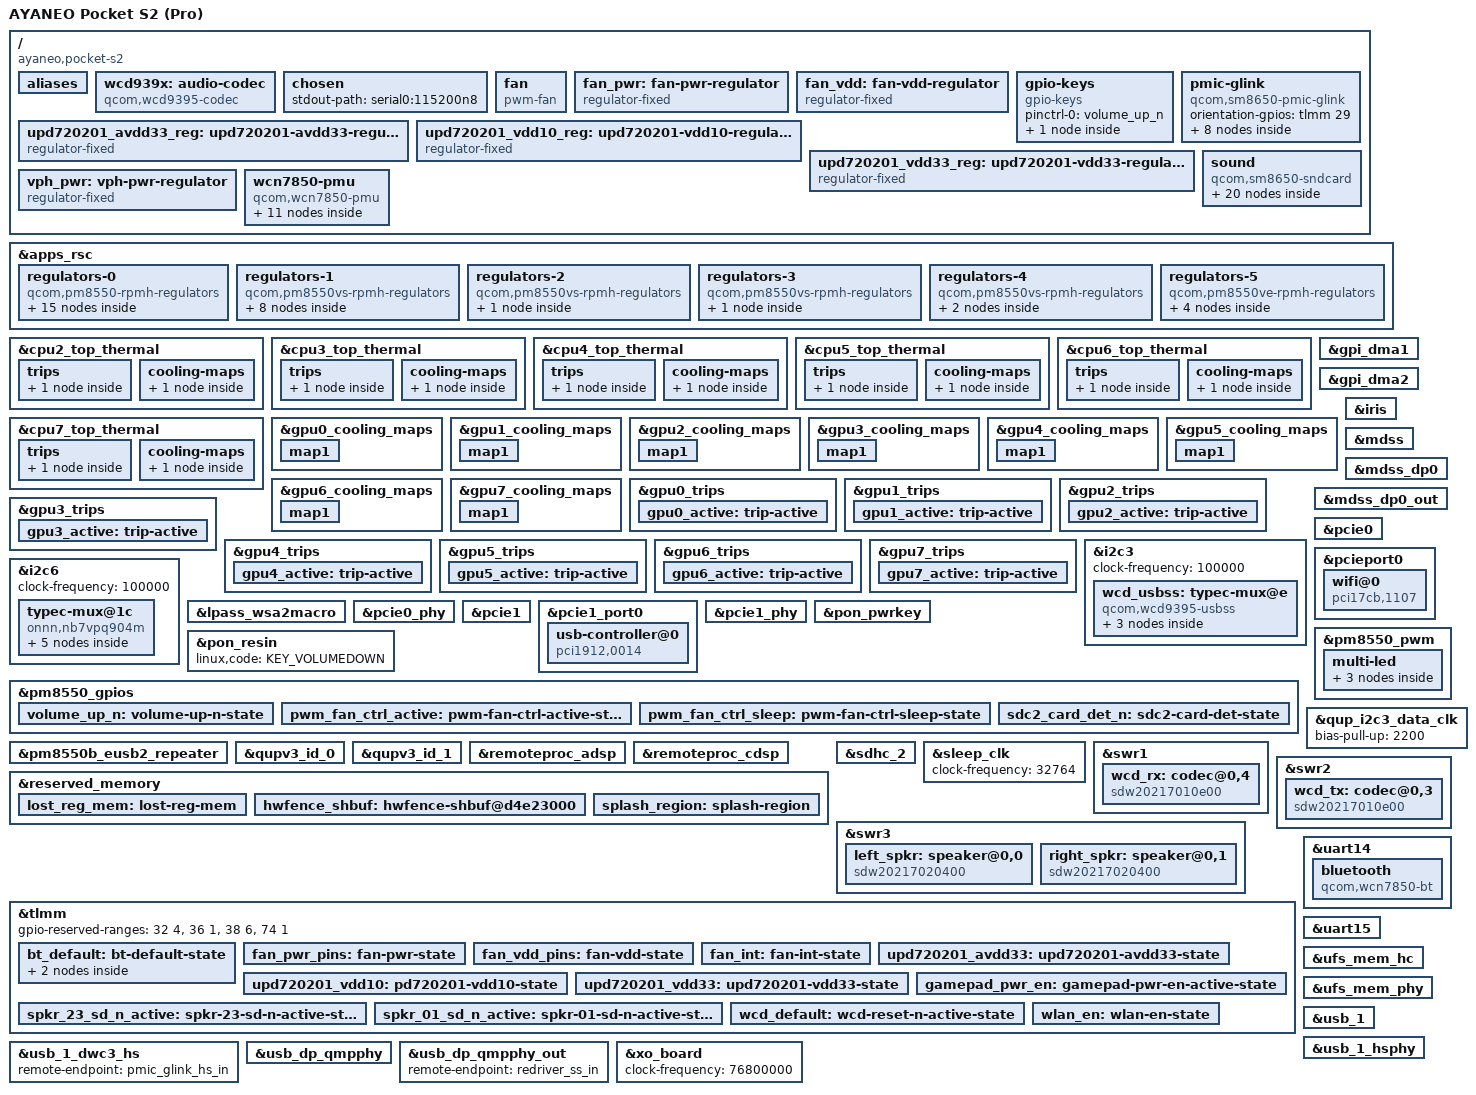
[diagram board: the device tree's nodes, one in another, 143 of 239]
// SPDX-License-Identifier: BSD-3-Clause
/*
 * Copyright (c) 2023, Linaro Limited
 * Copyright (c) 2025, Kancy Joe <kancy2333@outlook.com>
 */

/dts-v1/;

#include <dt-bindings/leds/common.h>
#include <dt-bindings/pinctrl/qcom,pmic-gpio.h>
#include <dt-bindings/regulator/qcom,rpmh-regulator.h>
#include "sm8650.dtsi"
#include "pm8550.dtsi"
#include "pm8550b.dtsi"
#define PMK8550VE_SID 8
#include "pm8550ve.dtsi"
#include "pm8550vs.dtsi"
#include "pmk8550.dtsi"

/delete-node/ &rmtfs_mem;
/delete-node/ &hwfence_shbuf;

/ {
	model = "AYANEO Pocket S2 (Pro)";
	compatible = "ayaneo,pocket-s2", "qcom,sm8650";
	chassis-type = "handset";

	aliases {
		serial0 = &uart15;
		serial1 = &uart14;
	};

	wcd939x: audio-codec {
		compatible = "qcom,wcd9395-codec", "qcom,wcd9390-codec";

		pinctrl-0 = <&wcd_default>;
		pinctrl-names = "default";

		qcom,micbias1-microvolt = <1800000>;
		qcom,micbias2-microvolt = <1800000>;
		qcom,micbias3-microvolt = <1800000>;
		qcom,micbias4-microvolt = <1800000>;
		qcom,mbhc-buttons-vthreshold-microvolt = <75000 150000 237000 500000 500000 500000 500000 500000>;
		qcom,mbhc-headset-vthreshold-microvolt = <1700000>;
		qcom,mbhc-headphone-vthreshold-microvolt = <50000>;
		qcom,rx-device = <&wcd_rx>;
		qcom,tx-device = <&wcd_tx>;

		reset-gpios = <&tlmm 107 GPIO_ACTIVE_LOW>;

		vdd-buck-supply = <&vreg_l15b_1p8>;
		vdd-rxtx-supply = <&vreg_l15b_1p8>;
		vdd-io-supply = <&vreg_l15b_1p8>;
		vdd-mic-bias-supply = <&vreg_bob1>;

		#sound-dai-cells = <1>;
	};

	chosen {
		stdout-path = "serial0:115200n8";
	};

	fan: fan {
		compatible = "pwm-fan";

		interrupts-extended = <&tlmm 14 IRQ_TYPE_EDGE_FALLING>;

		pwms = <&pm8550_pwm 3 50000>;

		fan-supply = <&fan_pwr>;

		#cooling-cells = <2>;
		cooling-levels = <0 16 32 45 60 80 105 130 155 180 205 230 255>;

		pinctrl-0 = <&fan_int>, <&pwm_fan_ctrl_active>;
		pinctrl-1 = <&pwm_fan_ctrl_sleep>;
		pinctrl-names = "default", "sleep";
	};

	fan_pwr: fan-pwr-regulator {
		compatible = "regulator-fixed";

		regulator-name = "fan_pwr";
		regulator-min-microvolt = <5000000>;
		regulator-max-microvolt = <5000000>;

		gpios = <&tlmm 125 GPIO_ACTIVE_HIGH>;
		enable-active-high;

		vin-supply = <&fan_vdd>;

		pinctrl-0 = <&fan_pwr_pins>;
		pinctrl-names = "default";
	};

	fan_vdd: fan-vdd-regulator {
		compatible = "regulator-fixed";

		regulator-name = "fan_vdd";
		regulator-min-microvolt = <5000000>;
		regulator-max-microvolt = <5000000>;

		gpios = <&tlmm 124 GPIO_ACTIVE_HIGH>;
		enable-active-high;

		vin-supply = <&vph_pwr>;

		pinctrl-0 = <&fan_vdd_pins>;
		pinctrl-names = "default";
	};

	gpio-keys {
		compatible = "gpio-keys";

		pinctrl-0 = <&volume_up_n>;
		pinctrl-names = "default";

		key-volume-up {
			label = "Volume Up";
			linux,code = <KEY_VOLUMEUP>;
			gpios = <&pm8550_gpios 6 GPIO_ACTIVE_LOW>;
			debounce-interval = <15>;
			linux,can-disable;
			wakeup-source;
		};
	};

	pmic-glink {
		compatible = "qcom,sm8650-pmic-glink",
			     "qcom,sm8550-pmic-glink",
			     "qcom,pmic-glink";
		#address-cells = <1>;
		#size-cells = <0>;

		orientation-gpios = <&tlmm 29 GPIO_ACTIVE_HIGH>;

		connector@0 {
			compatible = "usb-c-connector";
			reg = <0>;

			power-role = "dual";
			data-role = "dual";

			ports {
				#address-cells = <1>;
				#size-cells = <0>;

				port@0 {
					reg = <0>;

					pmic_glink_hs_in: endpoint {
						remote-endpoint = <&usb_1_dwc3_hs>;
					};
				};

				port@1 {
					reg = <1>;

					pmic_glink_ss_in: endpoint {
						remote-endpoint = <&redriver_ss_out>;
					};
				};

				port@2 {
					reg = <2>;

					pmic_glink_sbu: endpoint {
						remote-endpoint = <&wcd_usbss_sbu_mux>;
					};
				};
			};
		};
	};

	upd720201_avdd33_reg: upd720201-avdd33-regulator {
		compatible = "regulator-fixed";

		regulator-name = "upd720201_avdd33";
		regulator-min-microvolt = <3300000>;
		regulator-max-microvolt = <3300000>;

		gpios = <&tlmm 123 GPIO_ACTIVE_HIGH>;
		enable-active-high;

		vin-supply = <&vph_pwr>;

		pinctrl-0 = <&upd720201_avdd33>;
		pinctrl-names = "default";
	};

	upd720201_vdd10_reg: upd720201-vdd10-regulator {
		compatible = "regulator-fixed";

		regulator-name = "upd720201_vdd10";
		regulator-min-microvolt = <1050000>;
		regulator-max-microvolt = <1050000>;

		gpios = <&tlmm 122 GPIO_ACTIVE_HIGH>;
		enable-active-high;

		vin-supply = <&vph_pwr>;

		pinctrl-0 = <&upd720201_vdd10>;
		pinctrl-names = "default";
	};

	upd720201_vdd33_reg: upd720201-vdd33-regulator {
		compatible = "regulator-fixed";

		regulator-name = "upd720201_vdd33";
		regulator-min-microvolt = <3300000>;
		regulator-max-microvolt = <3300000>;

		gpios = <&tlmm 121 GPIO_ACTIVE_HIGH>;
		enable-active-high;

		vin-supply = <&vph_pwr>;

		pinctrl-0 = <&upd720201_vdd33>;
		pinctrl-names = "default";
	};

	sound {
		compatible = "qcom,sm8650-sndcard", "qcom,sm8450-sndcard";
		model = "SM8650-APS2";
		audio-routing = "SpkrLeft IN", "WSA_SPK1 OUT",
				"SpkrRight IN", "WSA_SPK2 OUT",
				"IN1_HPHL", "HPHL_OUT",
				"IN2_HPHR", "HPHR_OUT",
				"AMIC1", "MIC BIAS1",
				"AMIC2", "MIC BIAS2",
				"AMIC3", "MIC BIAS3",
				"AMIC4", "MIC BIAS3",
				"AMIC5", "MIC BIAS4",
				"TX SWR_INPUT0", "ADC1_OUTPUT",
				"TX SWR_INPUT1", "ADC2_OUTPUT",
				"TX SWR_INPUT7", "DMIC1_OUTPUT",
				"TX SWR_INPUT8", "DMIC2_OUTPUT";

		wcd-playback-dai-link {
			link-name = "WCD Playback";

			codec {
				sound-dai = <&wcd939x 0>,
					    <&swr1 0>,
					    <&lpass_rxmacro 0>;
			};

			cpu {
				sound-dai = <&q6apmbedai RX_CODEC_DMA_RX_0>;
			};

			platform {
				sound-dai = <&q6apm>;
			};
		};

		wcd-capture-dai-link {
			link-name = "WCD Capture";
			codec {
				sound-dai = <&wcd939x 1>,
					    <&swr2 0>,
					    <&lpass_txmacro 0>;
			};

			cpu {
				sound-dai = <&q6apmbedai TX_CODEC_DMA_TX_3>;
			};


			platform {
				sound-dai = <&q6apm>;
			};
		};

		wsa-dai-link {
			link-name = "WSA Playback";

			codec {
				sound-dai = <&right_spkr>,
					    <&left_spkr>,
					    <&swr3 0>,
					    <&lpass_wsa2macro 0>;
			};

			cpu {
				sound-dai = <&q6apmbedai WSA_CODEC_DMA_RX_0>;
			};

			platform {
				sound-dai = <&q6apm>;
			};
		};

		va-dai-link {
			link-name = "VA Capture";

			codec {
				sound-dai = <&lpass_vamacro 0>;
			};

			cpu {
				sound-dai = <&q6apmbedai VA_CODEC_DMA_TX_0>;
			};

			platform {
				sound-dai = <&q6apm>;
			};
		};

		dp-dai-link {
			link-name = "DisplayPort Playback";

			codec {
				sound-dai = <&mdss_dp0>;
			};

			cpu {
				sound-dai = <&q6apmbedai DISPLAY_PORT_RX_0>;
			};

			platform {
				sound-dai = <&q6apm>;
			};
		};
	};

	vph_pwr: vph-pwr-regulator {
		compatible = "regulator-fixed";

		regulator-name = "vph_pwr";
		regulator-min-microvolt = <3700000>;
		regulator-max-microvolt = <3700000>;

		regulator-always-on;
		regulator-boot-on;
	};

	wcn7850-pmu {
		compatible = "qcom,wcn7850-pmu";

		pinctrl-names = "default";
		pinctrl-0 = <&wlan_en>, <&bt_default>;

		wlan-enable-gpios = <&tlmm 16 GPIO_ACTIVE_HIGH>;
		bt-enable-gpios = <&tlmm 17 GPIO_ACTIVE_HIGH>;

		vdd-supply = <&vreg_s4i_0p85>;
		vddio-supply = <&vreg_l15b_1p8>;
		vddio1p2-supply = <&vreg_l3c_1p2>;
		vddaon-supply = <&vreg_s2c_0p8>;
		vdddig-supply = <&vreg_s3c_0p9>;
		vddrfa1p2-supply = <&vreg_s1c_1p2>;
		vddrfa1p8-supply = <&vreg_s6c_1p8>;

		clocks = <&rpmhcc RPMH_RF_CLK1>;

		regulators {
			vreg_pmu_rfa_cmn: ldo0 {
				regulator-name = "vreg_pmu_rfa_cmn";
			};

			vreg_pmu_aon_0p59: ldo1 {
				regulator-name = "vreg_pmu_aon_0p59";
			};

			vreg_pmu_wlcx_0p8: ldo2 {
				regulator-name = "vreg_pmu_wlcx_0p8";
			};

			vreg_pmu_wlmx_0p85: ldo3 {
				regulator-name = "vreg_pmu_wlmx_0p85";
			};

			vreg_pmu_btcmx_0p85: ldo4 {
				regulator-name = "vreg_pmu_btcmx_0p85";
			};

			vreg_pmu_rfa_0p8: ldo5 {
				regulator-name = "vreg_pmu_rfa_0p8";
			};

			vreg_pmu_rfa_1p2: ldo6 {
				regulator-name = "vreg_pmu_rfa_1p2";
			};

			vreg_pmu_rfa_1p8: ldo7 {
				regulator-name = "vreg_pmu_rfa_1p8";
			};

			vreg_pmu_pcie_0p9: ldo8 {
				regulator-name = "vreg_pmu_pcie_0p9";
			};

			vreg_pmu_pcie_1p8: ldo9 {
				regulator-name = "vreg_pmu_pcie_1p8";
			};
		};
	};
};

&apps_rsc {
	regulators-0 {
		compatible = "qcom,pm8550-rpmh-regulators";

		vdd-bob1-supply = <&vph_pwr>;
		vdd-bob2-supply = <&vph_pwr>;
		vdd-l2-l13-l14-supply = <&vreg_bob1>;
		vdd-l3-supply = <&vreg_s1c_1p2>;
		vdd-l5-l16-supply = <&vreg_bob1>;
		vdd-l6-l7-supply = <&vreg_bob1>;
		vdd-l8-l9-supply = <&vreg_bob1>;
		vdd-l11-supply = <&vreg_s1c_1p2>;
		vdd-l12-supply = <&vreg_s6c_1p8>;
		vdd-l15-supply = <&vreg_s6c_1p8>;
		vdd-l17-supply = <&vreg_bob2>;

		qcom,pmic-id = "b";

		vreg_bob1: bob1 {
			regulator-name = "vreg_bob1";
			regulator-min-microvolt = <3296000>;
			regulator-max-microvolt = <3960000>;
			regulator-initial-mode = <RPMH_REGULATOR_MODE_HPM>;
		};

		vreg_bob2: bob2 {
			regulator-name = "vreg_bob2";
			regulator-min-microvolt = <2720000>;
			regulator-max-microvolt = <3008000>;
			regulator-initial-mode = <RPMH_REGULATOR_MODE_HPM>;
		};

		vreg_l2b_3p0: ldo2 {
			regulator-name = "vreg_l2b_3p0";
			regulator-min-microvolt = <3008000>;
			regulator-max-microvolt = <3008000>;
			regulator-initial-mode = <RPMH_REGULATOR_MODE_HPM>;
			regulator-allow-set-load;
			regulator-allowed-modes = <RPMH_REGULATOR_MODE_LPM
						   RPMH_REGULATOR_MODE_HPM>;
		};

		vreg_l5b_3p1: ldo5 {
			regulator-name = "vreg_l5b_3p1";
			regulator-min-microvolt = <3104000>;
			regulator-max-microvolt = <3104000>;
			regulator-initial-mode = <RPMH_REGULATOR_MODE_HPM>;
			regulator-allow-set-load;
			regulator-allowed-modes = <RPMH_REGULATOR_MODE_LPM
						   RPMH_REGULATOR_MODE_HPM>;
		};

		vreg_l6b_1p8: ldo6 {
			regulator-name = "vreg_l6b_1p8";
			regulator-min-microvolt = <1800000>;
			regulator-max-microvolt = <3008000>;
			regulator-initial-mode = <RPMH_REGULATOR_MODE_HPM>;
			regulator-allow-set-load;
			regulator-allowed-modes = <RPMH_REGULATOR_MODE_LPM
						   RPMH_REGULATOR_MODE_HPM>;
		};

		vreg_l7b_1p8: ldo7 {
			regulator-name = "vreg_l7b_1p8";
			regulator-min-microvolt = <1800000>;
			regulator-max-microvolt = <3008000>;
			regulator-initial-mode = <RPMH_REGULATOR_MODE_HPM>;
		};

		vreg_l8b_1p8: ldo8 {
			regulator-name = "vreg_l8b_1p8";
			regulator-min-microvolt = <1800000>;
			regulator-max-microvolt = <3008000>;
			regulator-initial-mode = <RPMH_REGULATOR_MODE_HPM>;
			regulator-allow-set-load;
			regulator-allowed-modes = <RPMH_REGULATOR_MODE_LPM
						   RPMH_REGULATOR_MODE_HPM>;
		};

		vreg_l9b_2p9: ldo9 {
			regulator-name = "vreg_l9b_2p9";
			regulator-min-microvolt = <2960000>;
			regulator-max-microvolt = <3008000>;
			regulator-initial-mode = <RPMH_REGULATOR_MODE_HPM>;
			regulator-allow-set-load;
			regulator-allowed-modes = <RPMH_REGULATOR_MODE_LPM
						   RPMH_REGULATOR_MODE_HPM>;
		};

		vreg_l11b_1p2: ldo11 {
			regulator-name = "vreg_l11b_1p2";
			regulator-min-microvolt = <1200000>;
			regulator-max-microvolt = <1504000>;
			regulator-initial-mode = <RPMH_REGULATOR_MODE_HPM>;
			regulator-allow-set-load;
			regulator-allowed-modes = <RPMH_REGULATOR_MODE_LPM
						   RPMH_REGULATOR_MODE_HPM>;
		};

		vreg_l12b_1p8: ldo12 {
			regulator-name = "vreg_l12b_1p8";
			regulator-min-microvolt = <1800000>;
			regulator-max-microvolt = <1800000>;
			regulator-initial-mode = <RPMH_REGULATOR_MODE_HPM>;
			regulator-allow-set-load;
			regulator-allowed-modes = <RPMH_REGULATOR_MODE_LPM
						   RPMH_REGULATOR_MODE_HPM>;
		};

		vreg_l13b_3p0: ldo13 {
			regulator-name = "vreg_l13b_3p0";
			regulator-min-microvolt = <3000000>;
			regulator-max-microvolt = <3000000>;
			regulator-initial-mode = <RPMH_REGULATOR_MODE_HPM>;
			regulator-allow-set-load;
			regulator-allowed-modes = <RPMH_REGULATOR_MODE_LPM
						   RPMH_REGULATOR_MODE_HPM>;
		};

		vreg_l14b_3p2: ldo14 {
			regulator-name = "vreg_l14b_3p2";
			regulator-min-microvolt = <3200000>;
			regulator-max-microvolt = <3200000>;
			regulator-initial-mode = <RPMH_REGULATOR_MODE_HPM>;
			regulator-allow-set-load;
			regulator-allowed-modes = <RPMH_REGULATOR_MODE_LPM
						   RPMH_REGULATOR_MODE_HPM>;
		};

		vreg_l15b_1p8: ldo15 {
			regulator-name = "vreg_l15b_1p8";
			regulator-min-microvolt = <1800000>;
			regulator-max-microvolt = <1800000>;
			regulator-initial-mode = <RPMH_REGULATOR_MODE_HPM>;
			regulator-allow-set-load;
			regulator-allowed-modes = <RPMH_REGULATOR_MODE_LPM
						   RPMH_REGULATOR_MODE_HPM>;
		};

		vreg_l16b_2p8: ldo16 {
			regulator-name = "vreg_l16b_2p8";
			regulator-min-microvolt = <2800000>;
			regulator-max-microvolt = <2800000>;
			regulator-initial-mode = <RPMH_REGULATOR_MODE_HPM>;
			regulator-allow-set-load;
			regulator-allowed-modes = <RPMH_REGULATOR_MODE_LPM
						   RPMH_REGULATOR_MODE_HPM>;
			regulator-always-on;
			regulator-boot-on;
		};

		vreg_l17b_2p5: ldo17 {
			regulator-name = "vreg_l17b_2p5";
			regulator-min-microvolt = <2504000>;
			regulator-max-microvolt = <2504000>;
			regulator-initial-mode = <RPMH_REGULATOR_MODE_HPM>;
			regulator-allow-set-load;
			regulator-allowed-modes = <RPMH_REGULATOR_MODE_LPM
						   RPMH_REGULATOR_MODE_HPM>;
		};
	};

	regulators-1 {
		compatible = "qcom,pm8550vs-rpmh-regulators";

		vdd-l1-supply = <&vreg_s1c_1p2>;
		vdd-l2-supply = <&vreg_s1c_1p2>;
		vdd-l3-supply = <&vreg_s1c_1p2>;
		vdd-s1-supply = <&vph_pwr>;
		vdd-s2-supply = <&vph_pwr>;
		vdd-s3-supply = <&vph_pwr>;
		vdd-s4-supply = <&vph_pwr>;
		vdd-s5-supply = <&vph_pwr>;
		vdd-s6-supply = <&vph_pwr>;

		qcom,pmic-id = "c";

		vreg_s1c_1p2: smps1 {
			regulator-name = "vreg_s1c_1p2";
			regulator-min-microvolt = <1256000>;
			regulator-max-microvolt = <1348000>;
			regulator-initial-mode = <RPMH_REGULATOR_MODE_HPM>;
		};

		vreg_s2c_0p8: smps2 {
			regulator-name = "vreg_s2c_0p8";
			regulator-min-microvolt = <852000>;
			regulator-max-microvolt = <1036000>;
			regulator-initial-mode = <RPMH_REGULATOR_MODE_HPM>;
		};

		vreg_s3c_0p9: smps3 {
			regulator-name = "vreg_s3c_0p9";
			regulator-min-microvolt = <976000>;
			regulator-max-microvolt = <1064000>;
			regulator-initial-mode = <RPMH_REGULATOR_MODE_HPM>;
		};

		vreg_s4c_1p2: smps4 {
			regulator-name = "vreg_s4c_1p2";
			regulator-min-microvolt = <1224000>;
			regulator-max-microvolt = <1280000>;
			regulator-initial-mode = <RPMH_REGULATOR_MODE_HPM>;
		};

		vreg_s5c_0p7: smps5 {
			regulator-name = "vreg_s5c_0p7";
			regulator-min-microvolt = <752000>;
			regulator-max-microvolt = <900000>;
			regulator-initial-mode = <RPMH_REGULATOR_MODE_HPM>;
		};

		vreg_s6c_1p8: smps6 {
			regulator-name = "vreg_s6c_1p8";
			regulator-min-microvolt = <1856000>;
			regulator-max-microvolt = <2000000>;
			regulator-initial-mode = <RPMH_REGULATOR_MODE_HPM>;
		};

		vreg_l1c_1p2: ldo1 {
			regulator-name = "vreg_l1c_1p2";
			regulator-min-microvolt = <1200000>;
			regulator-max-microvolt = <1200000>;
			regulator-initial-mode = <RPMH_REGULATOR_MODE_HPM>;
			regulator-allow-set-load;
			regulator-allowed-modes = <RPMH_REGULATOR_MODE_LPM
						   RPMH_REGULATOR_MODE_HPM>;
		};

		vreg_l3c_1p2: ldo3 {
			regulator-name = "vreg_l3c_1p2";
			regulator-min-microvolt = <1200000>;
			regulator-max-microvolt = <1200000>;
			regulator-initial-mode = <RPMH_REGULATOR_MODE_HPM>;
			regulator-allow-set-load;
			regulator-allowed-modes = <RPMH_REGULATOR_MODE_LPM
						   RPMH_REGULATOR_MODE_HPM>;
			regulator-always-on;
			regulator-boot-on;
		};
	};

	regulators-2 {
		compatible = "qcom,pm8550vs-rpmh-regulators";

		vdd-l1-supply = <&vreg_s3c_0p9>;

		qcom,pmic-id = "d";

		vreg_l1d_0p88: ldo1 {
			regulator-name = "vreg_l1d_0p88";
			regulator-min-microvolt = <912000>;
			regulator-max-microvolt = <920000>;
			regulator-initial-mode = <RPMH_REGULATOR_MODE_HPM>;
			regulator-allow-set-load;
			regulator-allowed-modes = <RPMH_REGULATOR_MODE_LPM
						   RPMH_REGULATOR_MODE_HPM>;
		};
	};

	regulators-3 {
		compatible = "qcom,pm8550vs-rpmh-regulators";

		vdd-l3-supply = <&vreg_s3c_0p9>;

		qcom,pmic-id = "e";

		vreg_l3e_0p9: ldo3 {
			regulator-name = "vreg_l3e_0p9";
			regulator-min-microvolt = <880000>;
			regulator-max-microvolt = <920000>;
			regulator-initial-mode = <RPMH_REGULATOR_MODE_HPM>;
			regulator-allow-set-load;
			regulator-allowed-modes = <RPMH_REGULATOR_MODE_LPM
						   RPMH_REGULATOR_MODE_HPM>;
		};
	};

	regulators-4 {
		compatible = "qcom,pm8550vs-rpmh-regulators";

		vdd-l1-supply = <&vreg_s3c_0p9>;
		vdd-l3-supply = <&vreg_s3c_0p9>;

		qcom,pmic-id = "g";

		vreg_l1g_0p91: ldo1 {
			regulator-name = "vreg_l1g_0p91";
			regulator-min-microvolt = <912000>;
			regulator-max-microvolt = <920000>;
			regulator-initial-mode = <RPMH_REGULATOR_MODE_HPM>;
			regulator-allow-set-load;
			regulator-allowed-modes = <RPMH_REGULATOR_MODE_LPM
						   RPMH_REGULATOR_MODE_HPM>;
		};

		vreg_l3g_0p91: ldo3 {
			regulator-name = "vreg_l3g_0p91";
			regulator-min-microvolt = <880000>;
			regulator-max-microvolt = <912000>;
			regulator-initial-mode = <RPMH_REGULATOR_MODE_HPM>;
			regulator-allow-set-load;
			regulator-allowed-modes = <RPMH_REGULATOR_MODE_LPM
						   RPMH_REGULATOR_MODE_HPM>;
		};
	};

	regulators-5 {
		compatible = "qcom,pm8550ve-rpmh-regulators";

		vdd-l1-supply = <&vreg_s3c_0p9>;
		vdd-l2-supply = <&vreg_s3c_0p9>;
		vdd-l3-supply = <&vreg_s1c_1p2>;
		vdd-s4-supply = <&vph_pwr>;

		qcom,pmic-id = "i";

		vreg_s4i_0p85: smps4 {
			regulator-name = "vreg_s4i_0p85";
			regulator-min-microvolt = <852000>;
			regulator-max-microvolt = <1004000>;
			regulator-initial-mode = <RPMH_REGULATOR_MODE_HPM>;
		};

		vreg_l1i_0p88: ldo1 {
			regulator-name = "vreg_l1i_0p88";
			regulator-min-microvolt = <880000>;
			regulator-max-microvolt = <912000>;
			regulator-initial-mode = <RPMH_REGULATOR_MODE_HPM>;
			regulator-allow-set-load;
			regulator-allowed-modes = <RPMH_REGULATOR_MODE_LPM
						   RPMH_REGULATOR_MODE_HPM>;
		};

		vreg_l2i_0p88: ldo2 {
			regulator-name = "vreg_l2i_0p88";
			regulator-min-microvolt = <880000>;
			regulator-max-microvolt = <912000>;
			regulator-initial-mode = <RPMH_REGULATOR_MODE_HPM>;
			regulator-allow-set-load;
			regulator-allowed-modes = <RPMH_REGULATOR_MODE_LPM
						   RPMH_REGULATOR_MODE_HPM>;
		};

		vreg_l3i_1p2: ldo3 {
			regulator-name = "vreg_l3i_0p91";
			regulator-min-microvolt = <1200000>;
			regulator-max-microvolt = <1200000>;
			regulator-initial-mode = <RPMH_REGULATOR_MODE_HPM>;
			regulator-allow-set-load;
			regulator-allowed-modes = <RPMH_REGULATOR_MODE_LPM
						   RPMH_REGULATOR_MODE_HPM>;
		};
	};
};

&cpu2_top_thermal {
	trips {
		cpu2_active: cpu2-active {
			temperature = <38000>;
			hysteresis = <2000>;
			type = "active";
		};
	};

	cooling-maps {
		map {
			trip = <&cpu2_active>;
			cooling-device = <&fan THERMAL_NO_LIMIT THERMAL_NO_LIMIT>;
		};
	};
};

&cpu3_top_thermal {
	trips {
		cpu3_active: cpu3-active {
			temperature = <38000>;
			hysteresis = <2000>;
			type = "active";
		};
	};

	cooling-maps {
		map {
			trip = <&cpu3_active>;
			cooling-device = <&fan THERMAL_NO_LIMIT THERMAL_NO_LIMIT>;
		};
	};
};

&cpu4_top_thermal {
	trips {
		cpu4_active: cpu4-active {
			temperature = <38000>;
			hysteresis = <2000>;
			type = "active";
		};
	};

	cooling-maps {
		map {
			trip = <&cpu4_active>;
			cooling-device = <&fan THERMAL_NO_LIMIT THERMAL_NO_LIMIT>;
		};
	};
};

&cpu5_top_thermal {
	trips {
		cpu5_active: cpu5-active {
			temperature = <38000>;
			hysteresis = <2000>;
			type = "active";
		};
	};

	cooling-maps {
		map {
			trip = <&cpu5_active>;
			cooling-device = <&fan THERMAL_NO_LIMIT THERMAL_NO_LIMIT>;
		};
	};
};

&cpu6_top_thermal {
	trips {
		cpu6_active: cpu6-active {
			temperature = <38000>;
			hysteresis = <2000>;
			type = "active";
		};
	};

	cooling-maps {
		map {
			trip = <&cpu6_active>;
			cooling-device = <&fan THERMAL_NO_LIMIT THERMAL_NO_LIMIT>;
		};
	};
};

&cpu7_top_thermal {
	trips {
		cpu7_active: cpu7-active {
			temperature = <38000>;
			hysteresis = <2000>;
			type = "active";
		};
	};

	cooling-maps {
		map {
			trip = <&cpu7_active>;
			cooling-device = <&fan THERMAL_NO_LIMIT THERMAL_NO_LIMIT>;
		};
	};
};

&gpi_dma1 {
	status = "okay";
};

&gpi_dma2 {
	status = "okay";
};

&gpu0_cooling_maps {
	map1 {
		trip = <&gpu0_active>;
		cooling-device = <&fan THERMAL_NO_LIMIT THERMAL_NO_LIMIT>;
	};
};

&gpu1_cooling_maps {
	map1 {
		trip = <&gpu1_active>;
		cooling-device = <&fan THERMAL_NO_LIMIT THERMAL_NO_LIMIT>;
	};
};

&gpu2_cooling_maps {
	map1 {
		trip = <&gpu2_active>;
		cooling-device = <&fan THERMAL_NO_LIMIT THERMAL_NO_LIMIT>;
	};
};

&gpu3_cooling_maps {
	map1 {
		trip = <&gpu3_active>;
		cooling-device = <&fan THERMAL_NO_LIMIT THERMAL_NO_LIMIT>;
	};
};

&gpu4_cooling_maps {
	map1 {
		trip = <&gpu4_active>;
		cooling-device = <&fan THERMAL_NO_LIMIT THERMAL_NO_LIMIT>;
	};
};

&gpu5_cooling_maps {
	map1 {
		trip = <&gpu5_active>;
		cooling-device = <&fan THERMAL_NO_LIMIT THERMAL_NO_LIMIT>;
	};
};

&gpu6_cooling_maps {
	map1 {
		trip = <&gpu6_active>;
		cooling-device = <&fan THERMAL_NO_LIMIT THERMAL_NO_LIMIT>;
	};
};

&gpu7_cooling_maps {
	map1 {
		trip = <&gpu7_active>;
		cooling-device = <&fan THERMAL_NO_LIMIT THERMAL_NO_LIMIT>;
	};
};

&gpu0_trips {
	gpu0_active: trip-active {
		temperature = <38000>;
		hysteresis = <2000>;
		type = "active";
	};
};

&gpu1_trips {
	gpu1_active: trip-active {
		temperature = <38000>;
		hysteresis = <2000>;
		type = "active";
	};
};

&gpu2_trips {
	gpu2_active: trip-active {
		temperature = <38000>;
		hysteresis = <2000>;
		type = "active";
	};
};

&gpu3_trips {
	gpu3_active: trip-active {
		temperature = <38000>;
		hysteresis = <2000>;
		type = "active";
	};
};

&gpu4_trips {
	gpu4_active: trip-active {
		temperature = <38000>;
		hysteresis = <2000>;
		type = "active";
	};
};

&gpu5_trips {
	gpu5_active: trip-active {
		temperature = <38000>;
		hysteresis = <2000>;
		type = "active";
	};
};

&gpu6_trips {
	gpu6_active: trip-active {
		temperature = <38000>;
		hysteresis = <2000>;
		type = "active";
	};

};

&gpu7_trips {
	gpu7_active: trip-active {
		temperature = <38000>;
		hysteresis = <2000>;
		type = "active";
	};
};

&i2c3 {
	clock-frequency = <100000>;

	status = "okay";

	wcd_usbss: typec-mux@e {
		compatible = "qcom,wcd9395-usbss", "qcom,wcd9390-usbss";
		reg = <0xe>;

		vdd-supply = <&vreg_l15b_1p8>;
		reset-gpios = <&tlmm 152 GPIO_ACTIVE_HIGH>;

		mode-switch;
		orientation-switch;

		ports {
			#address-cells = <1>;
			#size-cells = <0>;

			port@0 {
				reg = <0>;

				wcd_usbss_sbu_mux: endpoint {
					remote-endpoint = <&pmic_glink_sbu>;
				};
			};
		};
	};
};

&i2c6 {
	clock-frequency = <100000>;

	status = "okay";

	typec-mux@1c {
		compatible = "onnn,nb7vpq904m";
		reg = <0x1c>;

		vcc-supply = <&vreg_l15b_1p8>;

		retimer-switch;
		orientation-switch;

		ports {
			#address-cells = <1>;
			#size-cells = <0>;

			port@0 {
				reg = <0>;

				redriver_ss_out: endpoint {
					remote-endpoint = <&pmic_glink_ss_in>;
				};
			};

			port@1 {
				reg = <1>;

				redriver_ss_in: endpoint {
					remote-endpoint = <&usb_dp_qmpphy_out>;
				};
			};
		};
	};
};

&iris {
	status = "okay";
};

&lpass_wsa2macro {
	status = "okay";
};

&mdss {
	status = "okay";
};

&mdss_dp0 {
	status = "okay";
};

&mdss_dp0_out {
	status = "okay";
};

&pcie0 {
	wake-gpios = <&tlmm 96 GPIO_ACTIVE_HIGH>;
	perst-gpios = <&tlmm 94 GPIO_ACTIVE_LOW>;

	pinctrl-0 = <&pcie0_default_state>;
	pinctrl-names = "default";

	status = "okay";
};

&pcieport0 {
	wifi@0 {
		compatible = "pci17cb,1107";
		reg = <0x10000 0x0 0x0 0x0 0x0>;

		vddrfacmn-supply = <&vreg_pmu_rfa_cmn>;
		vddaon-supply = <&vreg_pmu_aon_0p59>;
		vddwlcx-supply = <&vreg_pmu_wlcx_0p8>;
		vddwlmx-supply = <&vreg_pmu_wlmx_0p85>;
		vddrfa0p8-supply = <&vreg_pmu_rfa_0p8>;
		vddrfa1p2-supply = <&vreg_pmu_rfa_1p2>;
		vddrfa1p8-supply = <&vreg_pmu_rfa_1p8>;
		vddpcie0p9-supply = <&vreg_pmu_pcie_0p9>;
		vddpcie1p8-supply = <&vreg_pmu_pcie_1p8>;
	};
};

&pcie0_phy {
	vdda-phy-supply = <&vreg_l1i_0p88>;
	vdda-pll-supply = <&vreg_l3i_1p2>;

	status = "okay";
};

&pcie1 {
	wake-gpios = <&tlmm 99 GPIO_ACTIVE_HIGH>;
	perst-gpios = <&tlmm 97 GPIO_ACTIVE_LOW>;

	pinctrl-0 = <&pcie1_default_state>;
	pinctrl-names = "default";

	status = "okay";
};

&pcie1_port0 {
	/* Renesas μPD720201 PCIe USB3.0 HOST CONTROLLER */
	usb-controller@0 {
		compatible = "pci1912,0014";
		reg = <0x10000 0x0 0x0 0x0 0x0>;

		avdd33-supply = <&upd720201_avdd33_reg>;
		vdd10-supply = <&upd720201_vdd10_reg>;
		vdd33-supply = <&upd720201_vdd33_reg>;

		pinctrl-0 = <&gamepad_pwr_en>;
		pinctrl-names = "default";
	};
};

&pcie1_phy {
	vdda-phy-supply = <&vreg_l3e_0p9>;
	vdda-pll-supply = <&vreg_l3i_1p2>;
	vdda-qref-supply = <&vreg_l1i_0p88>;

	status = "okay";
};

&pon_pwrkey {
	status = "okay";
};

&pon_resin {
	linux,code = <KEY_VOLUMEDOWN>;

	status = "okay";
};

&pm8550_gpios {
	volume_up_n: volume-up-n-state {
		pins = "gpio6";
		function = "normal";
		bias-pull-up;
		input-enable;
		power-source = <1>;
	};

	pwm_fan_ctrl_active: pwm-fan-ctrl-active-state {
		pins = "gpio9";
		function = "func1";
		bias-disable;
		power-source = <0>;
		qcom,drive-strength = <PMIC_GPIO_STRENGTH_LOW>;
	};

	pwm_fan_ctrl_sleep: pwm-fan-ctrl-sleep-state {
		pins = "gpio9";
		function = "normal";
		output-high;
		bias-disable;
		power-source = <0>;
		qcom,drive-strength = <PMIC_GPIO_STRENGTH_LOW>;
	};

	sdc2_card_det_n: sdc2-card-det-state {
		pins = "gpio12";
		function = "normal";
		bias-pull-up;
		input-enable;
		output-disable;
		power-source = <1>; /* 1.8 V */
	};
};

&pm8550_pwm {
	status = "okay";

	multi-led {
		color = <LED_COLOR_ID_RGB>;
		function = LED_FUNCTION_STATUS;
		label = "Power Status";

		#address-cells = <1>;
		#size-cells = <0>;

		led@1 {
			reg = <1>;
			color = <LED_COLOR_ID_RED>;
		};

		led@2 {
			reg = <2>;
			color = <LED_COLOR_ID_GREEN>;
		};

		led@3 {
			reg = <3>;
			color = <LED_COLOR_ID_BLUE>;
		};
	};
};

&pm8550b_eusb2_repeater {
	vdd18-supply = <&vreg_l15b_1p8>;
	vdd3-supply = <&vreg_l5b_3p1>;
};

&qup_i2c3_data_clk {
	/* Use internal I2C pull-up */
	bias-pull-up = <2200>;
};

&qupv3_id_0 {
	status = "okay";
};

&qupv3_id_1 {
	status = "okay";
};

&remoteproc_adsp {
	firmware-name = "qcom/sm8650/ayaneo/ps2/adsp.mbn",
			"qcom/sm8650/ayaneo/ps2/adsp_dtb.mbn";

	status = "okay";
};

&remoteproc_cdsp {
	firmware-name = "qcom/sm8650/ayaneo/ps2/cdsp.mbn",
			"qcom/sm8650/ayaneo/ps2/cdsp_dtb.mbn";

	status = "okay";
};

&reserved_memory {
	lost_reg_mem: lost-reg-mem {
		reg = <0 0x9b09c000 0 0x4000>;
		no-map;
	};

	hwfence_shbuf: hwfence-shbuf@d4e23000 {
		reg = <0 0xd4e23000 0 0x2dd000>;
		no-map;
	};

	splash_region: splash-region {
		label = "cont_splash_region";
		reg = <0 0xd5100000 0 0x2b00000>;
		no-map;
	};
};

&sdhc_2 {
	cd-gpios = <&pm8550_gpios 12 GPIO_ACTIVE_LOW>;

	vmmc-supply = <&vreg_l9b_2p9>;
	vqmmc-supply = <&vreg_l8b_1p8>;
	bus-width = <4>;
	no-sdio;
	no-mmc;

	pinctrl-0 = <&sdc2_default>, <&sdc2_card_det_n>;
	pinctrl-1 = <&sdc2_sleep>, <&sdc2_card_det_n>;
	pinctrl-names = "default", "sleep";

	status = "okay";
};

&sleep_clk {
	clock-frequency = <32764>;
};

&swr1 {
	status = "okay";

	/* WCD9395 RX */
	wcd_rx: codec@0,4 {
		compatible = "sdw20217010e00";
		reg = <0 4>;

		/*
		 * WCD9395 RX Port 1 (HPH_L/R)      <=> SWR1 Port 1 (HPH_L/R)
		 * WCD9395 RX Port 2 (CLSH)         <=> SWR1 Port 2 (CLSH)
		 * WCD9395 RX Port 3 (COMP_L/R)     <=> SWR1 Port 3 (COMP_L/R)
		 * WCD9395 RX Port 4 (LO)           <=> SWR1 Port 4 (LO)
		 * WCD9395 RX Port 5 (DSD_L/R)      <=> SWR1 Port 5 (DSD_L/R)
		 * WCD9395 RX Port 6 (HIFI_PCM_L/R) <=> SWR1 Port 9 (HIFI_PCM_L/R)
		 */
		qcom,rx-port-mapping = <1 2 3 4 5 9>;
	};
};

&swr2 {
	status = "okay";

	/* WCD9395 TX */
	wcd_tx: codec@0,3 {
		compatible = "sdw20217010e00";
		reg = <0 3>;

		/*
		 * WCD9395 TX Port 1 (ADC1,2,3,4)         <=> SWR2 Port 2 (TX SWR_INPUT 0,1,2,3)
		 * WCD9395 TX Port 2 (ADC3,4 & DMIC0,1)   <=> SWR2 Port 2 (TX SWR_INPUT 0,1,2,3)
		 * WCD9395 TX Port 3 (DMIC0,1,2,3 & MBHC) <=> SWR2 Port 3 (TX SWR_INPUT 4,5,6,7)
		 * WCD9395 TX Port 4 (DMIC4,5,6,7)        <=> SWR2 Port 4 (TX SWR_INPUT 8,9,10,11)
		 */
		qcom,tx-port-mapping = <2 2 3 4>;
	};
};

&swr3 {
	status = "okay";

	pinctrl-0 = <&wsa2_swr_active>, <&spkr_23_sd_n_active>;
	pinctrl-names = "default";

	/* WSA8845, Speaker Left */
	left_spkr: speaker@0,0 {
		compatible = "sdw20217020400";
		reg = <0 0>;
		#sound-dai-cells = <0>;
		reset-gpios = <&tlmm 77 GPIO_ACTIVE_LOW>;
		sound-name-prefix = "SpkrLeft";
		vdd-1p8-supply = <&vreg_l15b_1p8>;
		vdd-io-supply = <&vreg_l3c_1p2>;

		/*
		 * WSA8845 Port 1 (DAC)     <=> SWR3 Port 1 (SPKR_L)
		 * WSA8845 Port 2 (COMP)    <=> SWR3 Port 2 (SPKR_L_COMP)
		 * WSA8845 Port 3 (BOOST)   <=> SWR3 Port 3 (SPKR_L_BOOST)
		 * WSA8845 Port 4 (PBR)     <=> SWR3 Port 7 (PBR)
		 * WSA8845 Port 5 (VISENSE) <=> SWR3 Port 10 (SPKR_L_VI)
		 * WSA8845 Port 6 (CPS)     <=> SWR3 Port 13 (CPS)
		 */
		qcom,port-mapping = <1 2 3 7 10 13>;
	};

	/* WSA8845, Speaker Right */
	right_spkr: speaker@0,1 {
		compatible = "sdw20217020400";
		reg = <0 1>;
		#sound-dai-cells = <0>;
		reset-gpios = <&tlmm 77 GPIO_ACTIVE_LOW>;
		sound-name-prefix = "SpkrRight";
		vdd-1p8-supply = <&vreg_l15b_1p8>;
		vdd-io-supply = <&vreg_l3c_1p2>;

		/*
		 * WSA8845 Port 1 (DAC)     <=> SWR3 Port 4 (SPKR_R)
		 * WSA8845 Port 2 (COMP)    <=> SWR3 Port 5 (SPKR_R_COMP)
		 * WSA8845 Port 3 (BOOST)   <=> SWR3 Port 6 (SPKR_R_BOOST)
		 * WSA8845 Port 4 (PBR)     <=> SWR3 Port 7 (PBR)
		 * WSA8845 Port 5 (VISENSE) <=> SWR3 Port 11 (SPKR_R_VI)
		 * WSA8845 Port 6 (CPS)     <=> SWR3 Port 13 (CPS)
		 */
		qcom,port-mapping = <4 5 6 7 11 13>;
	};
};

&tlmm {
	/* Reserved I/Os for NFC */
	gpio-reserved-ranges = <32 4>, <36 1>, <38 6>, <74 1>;

	bt_default: bt-default-state {
		bt-en-pins {
			pins = "gpio17";
			function = "gpio";
			drive-strength = <16>;
			bias-disable;
		};

		sw-ctrl-pins {
			pins = "gpio18";
			function = "gpio";
			bias-pull-down;
		};
	};

	fan_pwr_pins: fan-pwr-state {
		pins = "gpio125";
		function = "gpio";
		drive-strength = <2>;
		bias-disable;
	};

	fan_vdd_pins: fan-vdd-state {
		pins = "gpio124";
		function = "gpio";
		drive-strength = <2>;
		bias-disable;
	};

	fan_int: fan-int-state {
		pins = "gpio14";
		function = "gpio";
		drive-strength = <2>;
		bias-pull-up;
	};

	upd720201_avdd33: upd720201-avdd33-state {
		pins = "gpio123";
		function = "gpio";
		drive-strength = <2>;
		bias-disable;
	};

	upd720201_vdd10: pd720201-vdd10-state {
		pins = "gpio122";
		function = "gpio";
		drive-strength = <2>;
		bias-disable;
	};

	upd720201_vdd33: upd720201-vdd33-state {
		pins = "gpio121";
		function = "gpio";
		drive-strength = <2>;
		bias-disable;
	};

	gamepad_pwr_en: gamepad-pwr-en-active-state {
		pins = "gpio28";
		function = "gpio";
		drive-strength = <2>;
		bias-disable;
		output-high;
	};

	spkr_23_sd_n_active: spkr-23-sd-n-active-state {
		pins = "gpio77";
		function = "gpio";
		drive-strength = <16>;
		bias-disable;
	};

	spkr_01_sd_n_active: spkr-01-sd-n-active-state {
		pins = "gpio21";
		function = "gpio";
		drive-strength = <16>;
		bias-disable;
	};

	wcd_default: wcd-reset-n-active-state {
		pins = "gpio107";
		function = "gpio";
		drive-strength = <16>;
		bias-disable;
	};

	wlan_en: wlan-en-state {
		pins = "gpio16";
		function = "gpio";
		drive-strength = <8>;
		bias-pull-down;
	};
};

&uart14 {
	status = "okay";

	bluetooth {
		compatible = "qcom,wcn7850-bt";

		vddrfacmn-supply = <&vreg_pmu_rfa_cmn>;
		vddaon-supply = <&vreg_pmu_aon_0p59>;
		vddwlcx-supply = <&vreg_pmu_wlcx_0p8>;
		vddwlmx-supply = <&vreg_pmu_wlmx_0p85>;
		vddrfa0p8-supply = <&vreg_pmu_rfa_0p8>;
		vddrfa1p2-supply = <&vreg_pmu_rfa_1p2>;
		vddrfa1p8-supply = <&vreg_pmu_rfa_1p8>;

		max-speed = <3200000>;
	};
};

&uart15 {
	status = "okay";
};

&ufs_mem_hc {
	reset-gpios = <&tlmm 210 GPIO_ACTIVE_LOW>;

	vcc-supply = <&vreg_l17b_2p5>;
	vcc-max-microamp = <1300000>;
	vccq-supply = <&vreg_l1c_1p2>;
	vccq-max-microamp = <1200000>;

	status = "okay";
};

&ufs_mem_phy {
	vdda-phy-supply = <&vreg_l1d_0p88>;
	vdda-pll-supply = <&vreg_l3i_1p2>;

	status = "okay";
};

/*
 * DPAUX -> WCD9395 -> USB_SBU -> USB-C
 * eUSB2 DP/DM -> PM85550HS -> eUSB2 DP/DM -> WCD9395 -> USB-C
 * USB SS -> NB7VPQ904MMUTWG -> USB-C
 */

&usb_1 {
	dr_mode = "otg";
	usb-role-switch;

	status = "okay";
};

&usb_1_dwc3_hs {
	remote-endpoint = <&pmic_glink_hs_in>;
};

&usb_1_hsphy {
	vdd-supply = <&vreg_l1i_0p88>;
	vdda12-supply = <&vreg_l3i_1p2>;

	phys = <&pm8550b_eusb2_repeater>;

	status = "okay";
};

&usb_dp_qmpphy {
	vdda-phy-supply = <&vreg_l3i_1p2>;
	vdda-pll-supply = <&vreg_l3g_0p91>;

	status = "okay";
};

&usb_dp_qmpphy_out {
	remote-endpoint = <&redriver_ss_in>;
};

&xo_board {
	clock-frequency = <76800000>;
};
